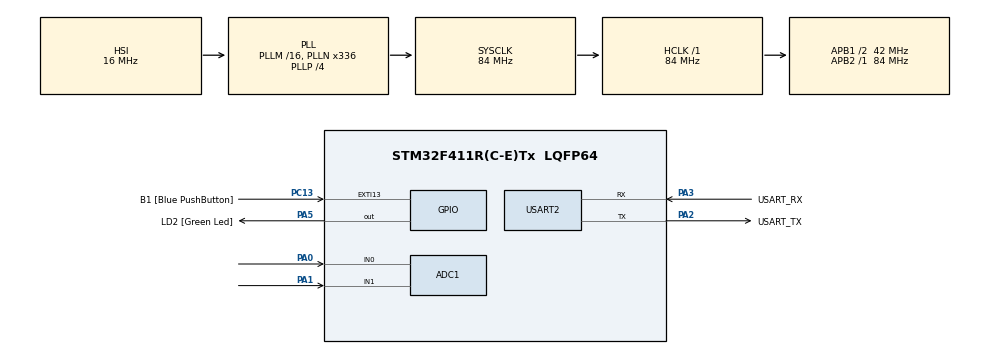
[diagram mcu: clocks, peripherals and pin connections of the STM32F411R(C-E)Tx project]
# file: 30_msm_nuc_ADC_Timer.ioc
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Mcu.Family=STM32F4
RCC.CortexFreq_Value=84000000
ADC1.ContinuousConvMode=ENABLE
PA14.GPIO_Label=TCK
RCC.SYSCLKSource=RCC_SYSCLKSOURCE_PLLCLK
ProjectManager.StackSize=0x400
PH0\ -\ OSC_IN.Signal=RCC_OSC_IN
RCC.HCLKFreq_Value=84000000
RCC.APB2TimFreq_Value=84000000
Dma.ADC1.0.Direction=DMA_PERIPH_TO_MEMORY
ADC1.InjNumberOfConversion=0
NVIC.DMA2_Stream0_IRQn=true\:0\:0\:false\:false\:true\:false\:true
Dma.ADC1.0.MemDataAlignment=DMA_MDATAALIGN_HALFWORD
RCC.AHBFreq_Value=84000000
ADC1.Channel-0\#ChannelRegularConversion=ADC_CHANNEL_0
RCC.HSE_VALUE=8000000
ADC1.ScanConvMode=ENABLE
PC13-ANTI_TAMP.Signal=GPXTI13
PC14-OSC32_IN.Mode=LSE-External-Oscillator
PA14.Mode=Serial_Wire
Dma.ADC1.0.PeriphInc=DMA_PINC_DISABLE
SH.ADCx_IN0.0=ADC1_IN0,IN0
ADC1.SamplingTime-0\#ChannelRegularConversion=ADC_SAMPLETIME_3CYCLES
RCC.FLatency-AdvancedSettings=FLASH_LATENCY_2
Mcu.Package=LQFP64
TIM2.Prescaler=839
USART2.VirtualMode=VM_ASYNC
PA2.GPIO_Label=USART_TX
TIM2.TIM_MasterOutputTrigger=TIM_TRGO_UPDATE
SH.ADCx_IN1.0=ADC1_IN1,IN1
RCC.APB1TimFreq_Value=84000000
Dma.ADC1.0.FIFOMode=DMA_FIFOMODE_DISABLE
Dma.Request0=ADC1
PA3.Signal=USART2_RX
PB3.GPIO_Label=SWO
PC15-OSC32_OUT.Mode=LSE-External-Oscillator
Dma.ADC1.0.Instance=DMA2_Stream0
ADC1.Rank-0\#ChannelRegularConversion=1
PC13-ANTI_TAMP.GPIO_Label=B1 [Blue PushButton]
PH1\ -\ OSC_OUT.Mode=HSE-External-Clock-Source
RCC.APB1CLKDivider=RCC_HCLK_DIV2
PC14-OSC32_IN.Signal=RCC_OSC32_IN
PA0-WKUP.Signal=ADCx_IN0
PA13.Signal=SYS_JTMS-SWDIO
PA3.Mode=Asynchronous
Dma.ADC1.0.PeriphDataAlignment=DMA_PDATAALIGN_HALFWORD
PH0\ -\ OSC_IN.Mode=HSE-External-Clock-Source
ProjectManager.TargetToolchain=STM32CubeIDE
Dma.ADC1.0.Mode=DMA_CIRCULAR
Dma.ADC1.0.Priority=DMA_PRIORITY_LOW
ADC1.Channel-1\#ChannelRegularConversion=ADC_CHANNEL_1
PC15-OSC32_OUT.Signal=RCC_OSC32_OUT
PA1.Signal=ADCx_IN1
PA5.Signal=GPIO_Output
PH1\ -\ OSC_OUT.Signal=RCC_OSC_OUT
board=NUCLEO-F411RE
RCC.VCOOutputFreq_Value=336000000
RCC.APB2Freq_Value=84000000
VP_TIM2_VS_ClockSourceINT.Mode=Internal
ADC1.DMAContinuousRequests=ENABLE
TIM2.Period=999
ADC1.NbrOfConversion=2
PA13.Mode=Serial_Wire
Mcu.Name=STM32F411R(C-E)Tx
PA13.GPIO_Label=TMS
PA2.Signal=USART2_TX
ADC1.ExternalTrigConv=ADC_EXTERNALTRIGCONV_T2_TRGO
RCC.48MHZClocksFreq_Value=84000000
PB3.Signal=SYS_JTDO-SWO
ADC1.SamplingTime-1\#ChannelRegularConversion=ADC_SAMPLETIME_3CYCLES
RCC.SYSCLKFreq_VALUE=84000000
ADC1.master=1
PA5.GPIO_Label=LD2 [Green Led]
ADC1.Rank-1\#ChannelRegularConversion=2
PC13-ANTI_TAMP.GPIO_ModeDefaultEXTI=GPIO_MODE_IT_FALLING
PA14.Signal=SYS_JTCK-SWCLK
Dma.ADC1.0.MemInc=DMA_MINC_ENABLE
ProjectManager.HeapSize=0x200
RCC.HSI_VALUE=16000000
RCC.PLLP=RCC_PLLP_DIV4
NVIC.PriorityGroup=NVIC_PRIORITYGROUP_0
ADC1.NbrOfConversionFlag=1
RCC.PLLN=336
PA2.Mode=Asynchronous
RCC.APB1Freq_Value=42000000
ADC1.ClockPrescaler=ADC_CLOCK_SYNC_PCLK_DIV8
PA3.GPIO_Label=USART_RX

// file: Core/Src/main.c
/* USER CODE BEGIN Header */
/**
  ******************************************************************************
  * @file           : main.c
  * @brief          : Main program body
  ******************************************************************************
  * @attention
  *
  * <h2><center>&copy; Copyright (c) 2021 STMicroelectronics.
  * All rights reserved.</center></h2>
  *
  * This software component is licensed by ST under BSD 3-Clause license,
  * the "License"; You may not use this file except in compliance with the
  * License. You may obtain a copy of the License at:
  *                        opensource.org/licenses/BSD-3-Clause
  *
  ******************************************************************************
  */
/* USER CODE END Header */
#include "main.h"
#include "adc.h"
#include "dma.h"
#include "tim.h"
#include "usart.h"
#include "gpio.h"

/* USER CODE BEGIN PV */
uint16_t AdcValue[2];
/* USER CODE END PV */

void SystemClock_Config(void);

int main(void)
{

  /* MCU Configuration--------------------------------------------------------*/

  /* Reset of all peripherals, Initializes the Flash interface and the Systick. */
  HAL_Init();

  /* Configure the system clock */
  SystemClock_Config();

  /* Initialize all configured peripherals */
  MX_GPIO_Init();
  MX_DMA_Init();
  MX_USART2_UART_Init();
  MX_ADC1_Init();
  MX_TIM2_Init();
  /* USER CODE BEGIN 2 */
  HAL_TIM_Base_Start(&htim2);
  HAL_ADC_Start_DMA(&hadc1, (uint32_t *)AdcValue, 2);
  /* USER CODE END 2 */

  /* Infinite loop */
  while (1)
  {

  }
}

void SystemClock_Config(void)
{
  RCC_OscInitTypeDef RCC_OscInitStruct = {0};
  RCC_ClkInitTypeDef RCC_ClkInitStruct = {0};

  /** Configure the main internal regulator output voltage
  */
  __HAL_RCC_PWR_CLK_ENABLE();
  __HAL_PWR_VOLTAGESCALING_CONFIG(PWR_REGULATOR_VOLTAGE_SCALE1);
  /** Initializes the RCC Oscillators according to the specified parameters
  * in the RCC_OscInitTypeDef structure.
  */
  RCC_OscInitStruct.OscillatorType = RCC_OSCILLATORTYPE_HSI;
  RCC_OscInitStruct.HSIState = RCC_HSI_ON;
  RCC_OscInitStruct.HSICalibrationValue = RCC_HSICALIBRATION_DEFAULT;
  RCC_OscInitStruct.PLL.PLLState = RCC_PLL_ON;
  RCC_OscInitStruct.PLL.PLLSource = RCC_PLLSOURCE_HSI;
  RCC_OscInitStruct.PLL.PLLM = 16;
  RCC_OscInitStruct.PLL.PLLN = 336;
  RCC_OscInitStruct.PLL.PLLP = RCC_PLLP_DIV4;
  RCC_OscInitStruct.PLL.PLLQ = 4;
  if (HAL_RCC_OscConfig(&RCC_OscInitStruct) != HAL_OK)
  {
    Error_Handler();
  }
  /** Initializes the CPU, AHB and APB buses clocks
  */
  RCC_ClkInitStruct.ClockType = RCC_CLOCKTYPE_HCLK|RCC_CLOCKTYPE_SYSCLK
                              |RCC_CLOCKTYPE_PCLK1|RCC_CLOCKTYPE_PCLK2;
  RCC_ClkInitStruct.SYSCLKSource = RCC_SYSCLKSOURCE_PLLCLK;
  RCC_ClkInitStruct.AHBCLKDivider = RCC_SYSCLK_DIV1;
  RCC_ClkInitStruct.APB1CLKDivider = RCC_HCLK_DIV2;
  RCC_ClkInitStruct.APB2CLKDivider = RCC_HCLK_DIV1;

  if (HAL_RCC_ClockConfig(&RCC_ClkInitStruct, FLASH_LATENCY_2) != HAL_OK)
  {
    Error_Handler();
  }
}

void Error_Handler(void)
{
  __disable_irq();
  while (1)
  {
  }
}

/************************ (C) COPYRIGHT STMicroelectronics *****END OF FILE****/
